# STM32F746ZGY7 register map
File version: 1.0
Registers are 32-bit, access not given, reset 0x0 unless marked. A register's access mark holds for its fields unless they carry their own. Offsets are from the block's base; [hi:lo] are bit positions; {n}, {i} and the like mark numbered series; 'fields as' and 'values as' point back to an identical list.

## ETH
Base 0x40028000
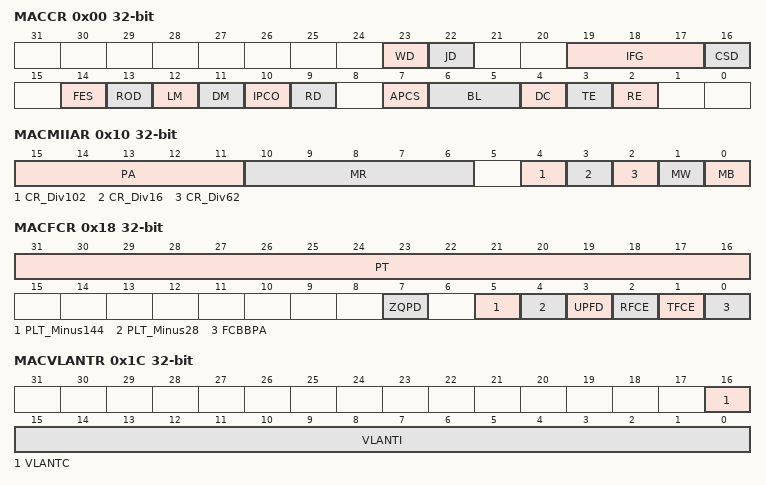
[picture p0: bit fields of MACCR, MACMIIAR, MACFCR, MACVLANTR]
0x00 MACCR
  [23] WD, [22] JD, [19:17] IFG, [16] CSD, [14] FES, [13] ROD, [12] LM, [11] DM, [10] IPCO, [9] RD, [7] APCS, [6:5] BL, [4] DC, [3] TE, [2] RE
0x04 MACFFR
  [31] RA, [10] HPF, [9] SAF, [8] SAIF, [7] PCF_ForwardAll, [7:6] PCF_ForwardPassedAddrFilter, [5] BFD, [4] PAM, [3] DAIF, [2] HM, [1] HU, [0] PM
0x08 MACHTHR
  [31:0] HTH
0x0C MACHTLR
  [31:0] HTL
0x10 MACMIIAR
  [15:11] PA, [10:6] MR, [4] CR_Div102, [3] CR_Div16, [2] CR_Div62, [1] MW, [0] MB
0x14 MACMIIDR
  [15:0] MD
0x18 MACFCR
  [31:16] PT, [7] ZQPD, [5] PLT_Minus144, [4] PLT_Minus28, [3] UPFD, [2] RFCE, [1] TFCE, [0] FCBBPA
0x1C MACVLANTR
  [16] VLANTC, [15:0] VLANTI
0x28 MACRWUFFR
  [31:0] D
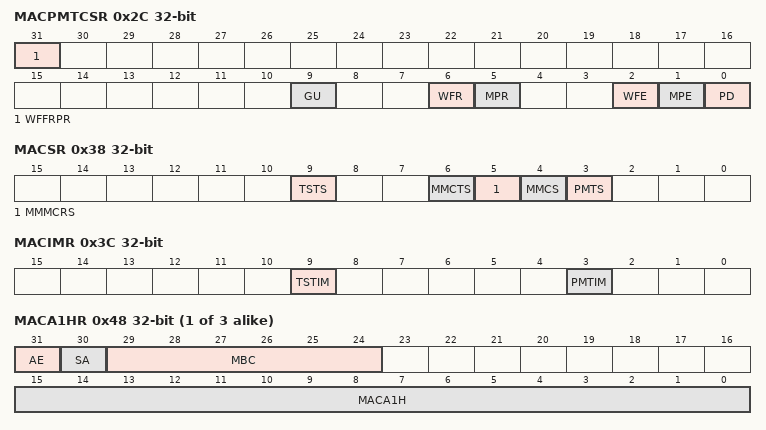
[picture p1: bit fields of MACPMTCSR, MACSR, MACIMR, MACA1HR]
0x2C MACPMTCSR
  [31] WFFRPR, [9] GU, [6] WFR, [5] MPR, [2] WFE, [1] MPE, [0] PD
0x34 MACDBGR
  [25] TFF, [24] TFNE, [22] TPWA, [21] TFRS_WAITING, [21:20] TFRS_WRITING, [19] MTP, [18] MTFCS_GENERATINGPCF, [17] MTFCS_WAITING, [16] MMTEA, [9] RFFL_ABOVEFCT, [9:8] RFFL_FULL, [6] RFRCS_STATUSREADING, [6:5] RFRCS_FLUSHING, [4] RFWRA, [2:1] MSFRWCS, [0] MMRPEA
0x38 MACSR
  [9] TSTS, [6] MMCTS, [5] MMMCRS, [4] MMCS, [3] PMTS
0x3C MACIMR
  [9] TSTIM, [3] PMTIM
0x40 MACA0HR
  [15:0] MACA0H
{0x44+8i} MACA{i}LR (i=0..3)
  [31:0] MACA{i}L
{0x40+8i} MACA{i}HR (i=1..3)
  [31] AE, [30] SA, [29:24] MBC, [15:0] MACA{i}H
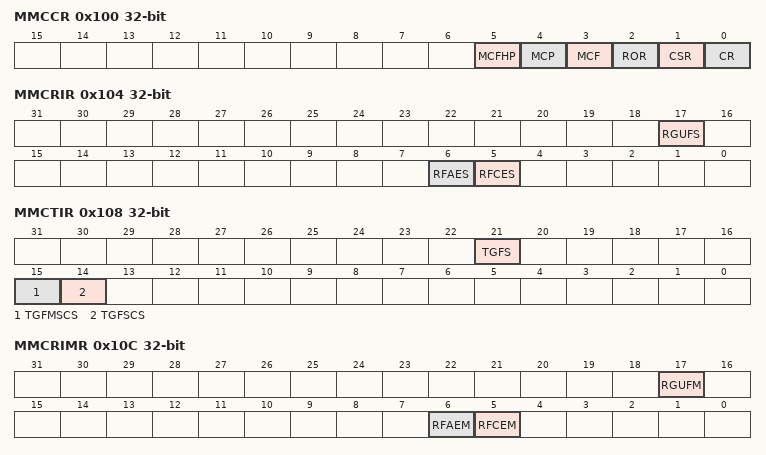
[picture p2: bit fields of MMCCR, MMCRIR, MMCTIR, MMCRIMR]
0x100 MMCCR
  [5] MCFHP, [4] MCP, [3] MCF, [2] ROR, [1] CSR, [0] CR
0x104 MMCRIR
  [17] RGUFS, [6] RFAES, [5] RFCES
0x108 MMCTIR
  [21] TGFS, [15] TGFMSCS, [14] TGFSCS
0x10C MMCRIMR
  [17] RGUFM, [6] RFAEM, [5] RFCEM
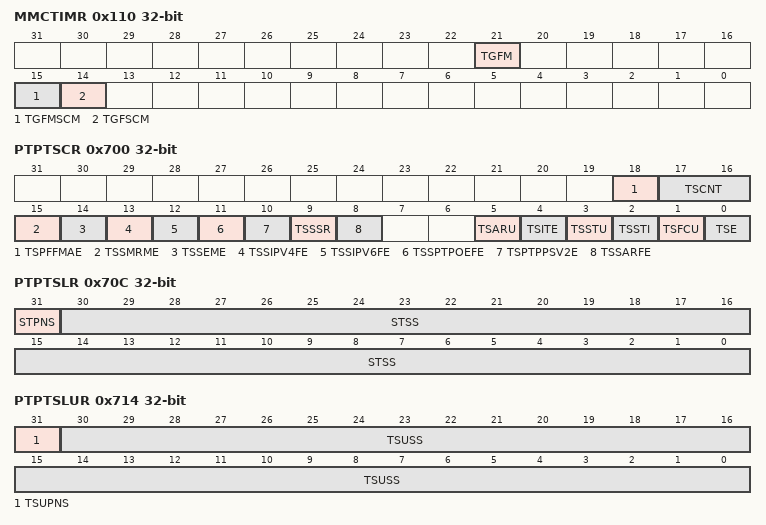
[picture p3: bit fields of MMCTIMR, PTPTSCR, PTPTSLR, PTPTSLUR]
0x110 MMCTIMR
  [21] TGFM, [15] TGFMSCM, [14] TGFSCM
0x14C MMCTGFSCCR
  [31:0] TGFSCC
0x150 MMCTGFMSCCR
  [31:0] TGFMSCC
0x168 MMCTGFCR
  [31:0] TGFC
0x194 MMCRFCECR
  [31:0] RFCEC
0x198 MMCRFAECR
  [31:0] RFAEC
0x1C4 MMCRGUFCR
  [31:0] RGUFC
0x700 PTPTSCR
  [18] TSPFFMAE, [17:16] TSCNT, [15] TSSMRME, [14] TSSEME, [13] TSSIPV4FE, [12] TSSIPV6FE, [11] TSSPTPOEFE, [10] TSPTPPSV2E, [9] TSSSR, [8] TSSARFE, [5] TSARU, [4] TSITE, [3] TSSTU, [2] TSSTI, [1] TSFCU, [0] TSE
0x704 PTPSSIR
  [7:0] STSSI
0x708 PTPTSHR
  [31:0] STS
0x70C PTPTSLR
  [31] STPNS, [30:0] STSS
0x710 PTPTSHUR
  [31:0] TSUS
0x714 PTPTSLUR
  [31] TSUPNS, [30:0] TSUSS
0x718 PTPTSAR
  [31:0] TSA
0x71C PTPTTHR
  [31:0] TTSH
0x720 PTPTTLR
  [31:0] TTSL
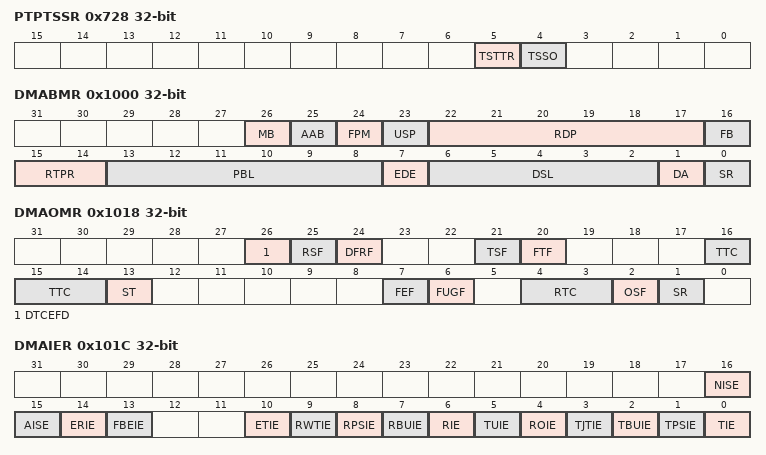
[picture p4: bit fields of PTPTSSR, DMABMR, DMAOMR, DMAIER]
0x728 PTPTSSR
  [5] TSTTR, [4] TSSO
0x72C PTPPPSCR
  [3:0] PPSFREQ
0x1000 DMABMR
  [26] MB, [25] AAB, [24] FPM, [23] USP, [22:17] RDP, [16] FB, [15:14] RTPR, [13:8] PBL, [7] EDE, [6:2] DSL, [1] DA, [0] SR
0x1004 DMATPDR
  [31:0] TPD
0x1008 DMARPDR
  [31:0] RPD
0x100C DMARDLAR
  [31:0] SRL
0x1010 DMATDLAR
  [31:0] STL
0x1014 DMASR
  [29] TSTS, [28] PMTS, [27] MMCS, [25] EBS_DescAccess, [24] EBS_ReadTransf, [23] EBS_DataTransfTx, [21] TPS_Waiting, [21:20] TPS_Reading, [19] RPS_Suspended, [18:17] RPS_Waiting, [16] NIS, [15] AIS, [14] ERS, [13] FBES, [10] ETS, [9] RWTS, [8] RPSS, [7] RBUS, [6] RS, [5] TUS, [4] ROS, [3] TJTS, [2] TBUS, [1] TPSS, [0] TS
0x1018 DMAOMR
  [26] DTCEFD, [25] RSF, [24] DFRF, [21] TSF, [20] FTF, [16:14] TTC, [13] ST, [7] FEF, [6] FUGF, [4:3] RTC, [2] OSF, [1] SR
0x101C DMAIER
  [16] NISE, [15] AISE, [14] ERIE, [13] FBEIE, [10] ETIE, [9] RWTIE, [8] RPSIE, [7] RBUIE, [6] RIE, [5] TUIE, [4] ROIE, [3] TJTIE, [2] TBUIE, [1] TPSIE, [0] TIE
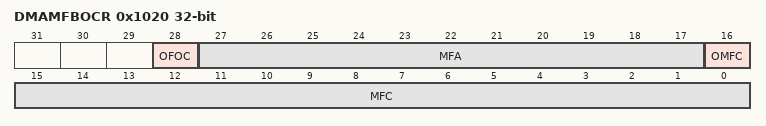
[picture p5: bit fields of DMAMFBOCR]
0x1020 DMAMFBOCR
  [28] OFOC, [27:17] MFA, [16] OMFC, [15:0] MFC
0x1024 DMARSWTR
0x1048 DMACHTDR
  [31:0] HTDAP
0x104C DMACHRDR
  [31:0] HRDAP
0x1050 DMACHTBAR
  [31:0] HTBAP
0x1054 DMACHRBAR
  [31:0] HRBAP

## USB_OTG_HS
Base 0x40040000
Same registers: USB_OTG_FS 0x50000000
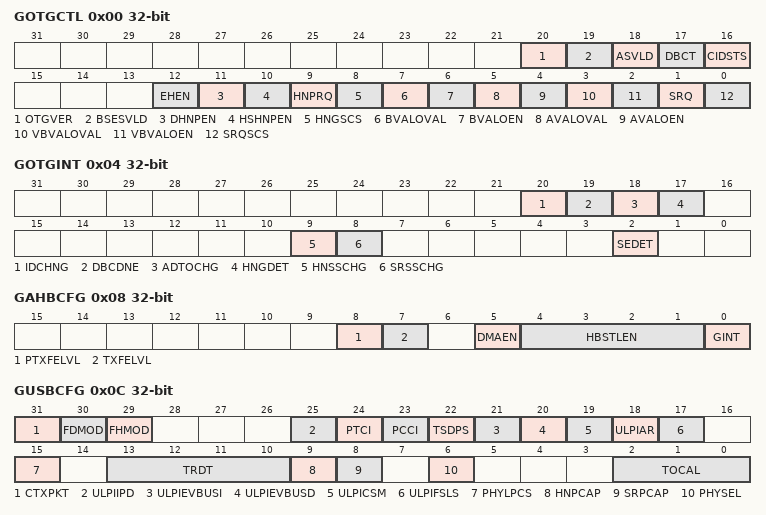
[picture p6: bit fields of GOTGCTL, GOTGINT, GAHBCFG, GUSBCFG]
0x00 GOTGCTL
  [20] OTGVER, [19] BSESVLD, [18] ASVLD, [17] DBCT, [16] CIDSTS, [12] EHEN, [11] DHNPEN, [10] HSHNPEN, [9] HNPRQ, [8] HNGSCS, [7] BVALOVAL, [6] BVALOEN, [5] AVALOVAL, [4] AVALOEN, [3] VBVALOVAL, [2] VBVALOEN, [1] SRQ, [0] SRQSCS
0x04 GOTGINT
  [20] IDCHNG, [19] DBCDNE, [18] ADTOCHG, [17] HNGDET, [9] HNSSCHG, [8] SRSSCHG, [2] SEDET
0x08 GAHBCFG
  [8] PTXFELVL, [7] TXFELVL, [5] DMAEN, [4:1] HBSTLEN, [0] GINT
0x0C GUSBCFG
  [31] CTXPKT, [30] FDMOD, [29] FHMOD, [25] ULPIIPD, [24] PTCI, [23] PCCI, [22] TSDPS, [21] ULPIEVBUSI, [20] ULPIEVBUSD, [19] ULPICSM, [18] ULPIAR, [17] ULPIFSLS, [15] PHYLPCS, [13:10] TRDT, [9] HNPCAP, [8] SRPCAP, [6] PHYSEL, [2:0] TOCAL
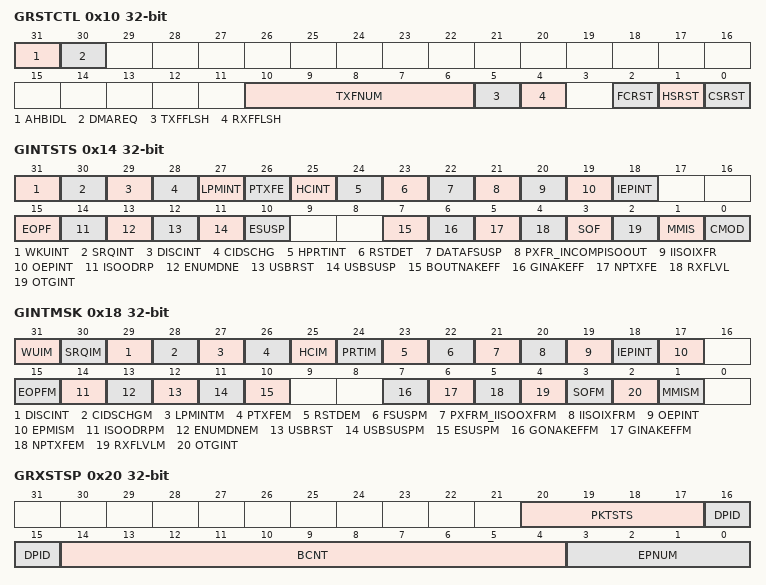
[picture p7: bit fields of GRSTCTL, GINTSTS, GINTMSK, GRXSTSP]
0x10 GRSTCTL
  [31] AHBIDL, [30] DMAREQ, [10:6] TXFNUM, [5] TXFFLSH, [4] RXFFLSH, [2] FCRST, [1] HSRST, [0] CSRST
0x14 GINTSTS
  [31] WKUINT, [30] SRQINT, [29] DISCINT, [28] CIDSCHG, [27] LPMINT, [26] PTXFE, [25] HCINT, [24] HPRTINT, [23] RSTDET, [22] DATAFSUSP, [21] PXFR_INCOMPISOOUT, [20] IISOIXFR, [19] OEPINT, [18] IEPINT, [15] EOPF, [14] ISOODRP, [13] ENUMDNE, [12] USBRST, [11] USBSUSP, [10] ESUSP, [7] BOUTNAKEFF, [6] GINAKEFF, [5] NPTXFE, [4] RXFLVL, [3] SOF, [2] OTGINT, [1] MMIS, [0] CMOD
0x18 GINTMSK
  [31] WUIM, [30] SRQIM, [29] DISCINT, [28] CIDSCHGM, [27] LPMINTM, [26] PTXFEM, [25] HCIM, [24] PRTIM, [23] RSTDEM, [22] FSUSPM, [21] PXFRM_IISOOXFRM, [20] IISOIXFRM, [19] OEPINT, [18] IEPINT, [17] EPMISM, [15] EOPFM, [14] ISOODRPM, [13] ENUMDNEM, [12] USBRST, [11] USBSUSPM, [10] ESUSPM, [7] GONAKEFFM, [6] GINAKEFFM, [5] NPTXFEM, [4] RXFLVLM, [3] SOFM, [2] OTGINT, [1] MMISM
0x1C GRXSTSR
0x20 GRXSTSP
  [20:17] PKTSTS, [16:15] DPID, [14:4] BCNT, [3:0] EPNUM
0x24 GRXFSIZ
  [15:0] RXFD
0x28 DIEPTXF0_HNPTXFSIZ
0x2C HNPTXSTS
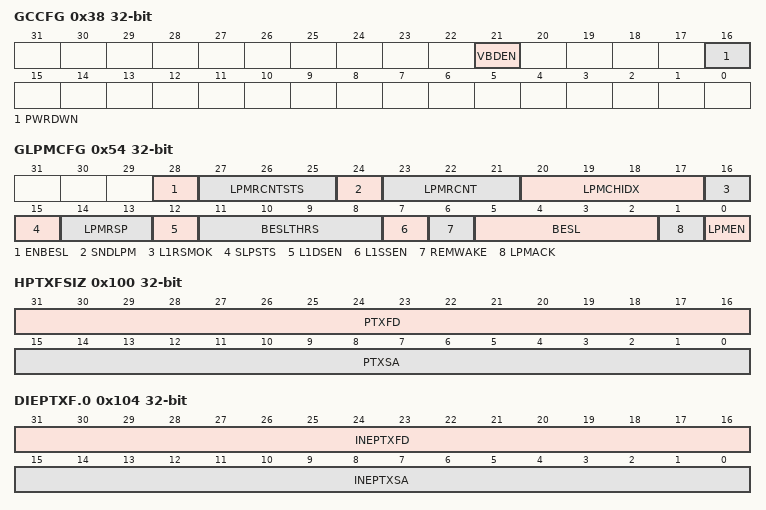
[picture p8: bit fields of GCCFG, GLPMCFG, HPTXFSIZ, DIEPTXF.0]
0x38 GCCFG
  [21] VBDEN, [16] PWRDWN
0x3C CID
  [31:0] PRODUCT_ID
0x4C GHWCFG3
0x54 GLPMCFG
  [28] ENBESL, [27:25] LPMRCNTSTS, [24] SNDLPM, [23:21] LPMRCNT, [20:17] LPMCHIDX, [16] L1RSMOK, [15] SLPSTS, [14:13] LPMRSP, [12] L1DSEN, [11:8] BESLTHRS, [7] L1SSEN, [6] REMWAKE, [5:2] BESL, [1] LPMACK, [0] LPMEN
0x5C GDFIFOCFG
0x100 HPTXFSIZ
  [31:16] PTXFD, [15:0] PTXSA
0x104 DIEPTXF.0
  [31:16] INEPTXFD, [15:0] INEPTXSA
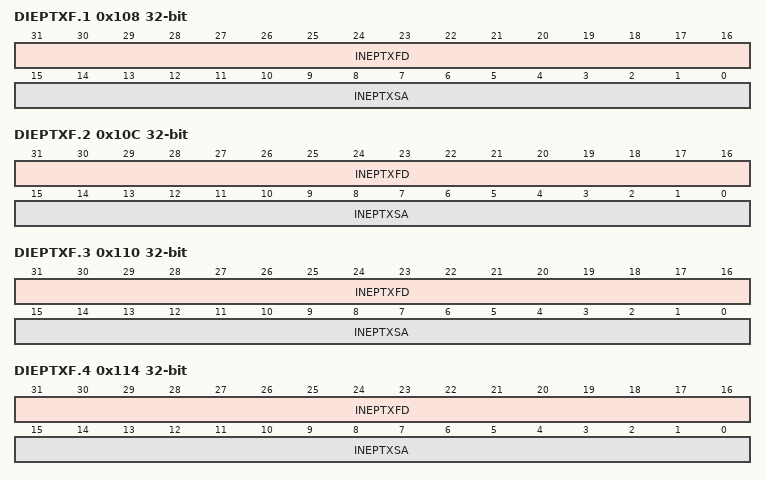
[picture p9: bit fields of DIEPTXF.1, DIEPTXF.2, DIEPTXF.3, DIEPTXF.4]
0x108 DIEPTXF.1
  [31:16] INEPTXFD, [15:0] INEPTXSA
0x10C DIEPTXF.2
  [31:16] INEPTXFD, [15:0] INEPTXSA
0x110 DIEPTXF.3
  [31:16] INEPTXFD, [15:0] INEPTXSA
0x114 DIEPTXF.4
  [31:16] INEPTXFD, [15:0] INEPTXSA
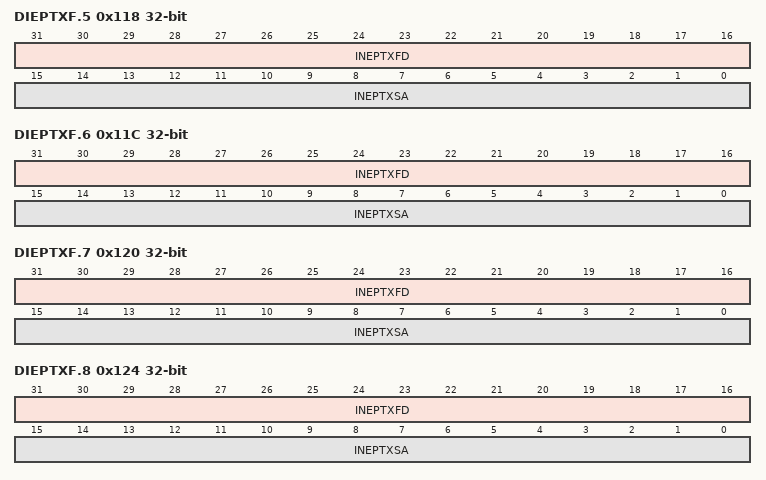
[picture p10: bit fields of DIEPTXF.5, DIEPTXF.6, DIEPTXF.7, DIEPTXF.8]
0x118 DIEPTXF.5
  [31:16] INEPTXFD, [15:0] INEPTXSA
0x11C DIEPTXF.6
  [31:16] INEPTXFD, [15:0] INEPTXSA
0x120 DIEPTXF.7
  [31:16] INEPTXFD, [15:0] INEPTXSA
0x124 DIEPTXF.8
  [31:16] INEPTXFD, [15:0] INEPTXSA
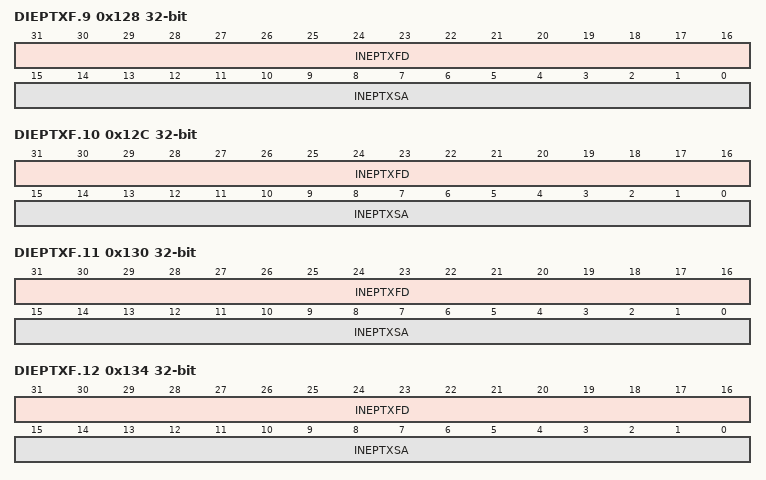
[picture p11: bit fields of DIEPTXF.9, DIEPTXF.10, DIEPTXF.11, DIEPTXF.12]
0x128 DIEPTXF.9
  [31:16] INEPTXFD, [15:0] INEPTXSA
0x12C DIEPTXF.10
  [31:16] INEPTXFD, [15:0] INEPTXSA
0x130 DIEPTXF.11
  [31:16] INEPTXFD, [15:0] INEPTXSA
0x134 DIEPTXF.12
  [31:16] INEPTXFD, [15:0] INEPTXSA
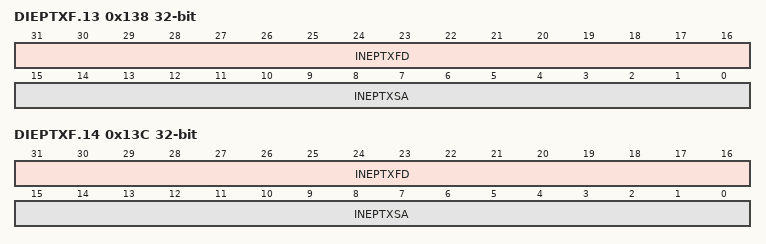
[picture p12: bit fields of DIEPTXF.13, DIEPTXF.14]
0x138 DIEPTXF.13
  [31:16] INEPTXFD, [15:0] INEPTXSA
0x13C DIEPTXF.14
  [31:16] INEPTXFD, [15:0] INEPTXSA

## DCMI
Base 0x50050000
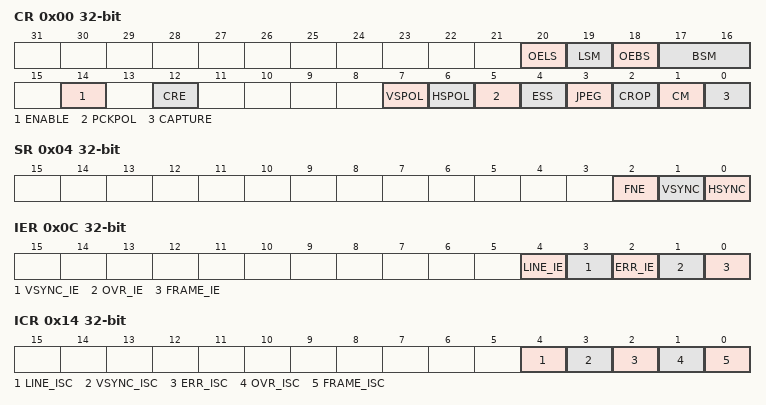
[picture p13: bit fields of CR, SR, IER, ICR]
0x00 CR
  [20] OELS, [19] LSM, [18] OEBS, [17:16] BSM, [14] ENABLE, [12] CRE, [7] VSPOL, [6] HSPOL, [5] PCKPOL, [4] ESS, [3] JPEG, [2] CROP, [1] CM, [0] CAPTURE
0x04 SR
  [2] FNE, [1] VSYNC, [0] HSYNC
0x08 RISR
0x0C IER
  [4] LINE_IE, [3] VSYNC_IE, [2] ERR_IE, [1] OVR_IE, [0] FRAME_IE
0x10 MISR
0x14 ICR
  [4] LINE_ISC, [3] VSYNC_ISC, [2] ERR_ISC, [1] OVR_ISC, [0] FRAME_ISC
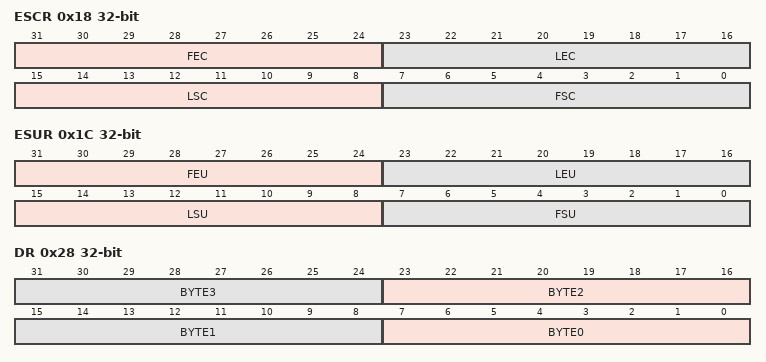
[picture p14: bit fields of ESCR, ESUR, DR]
0x18 ESCR
  [31:24] FEC, [23:16] LEC, [15:8] LSC, [7:0] FSC
0x1C ESUR
  [31:24] FEU, [23:16] LEU, [15:8] LSU, [7:0] FSU
0x20 CWSTRTR
0x24 CWSIZER
0x28 DR
  [8n+7:8n] BYTE{n} (n=0..3)

## RNG
Base 0x50060800
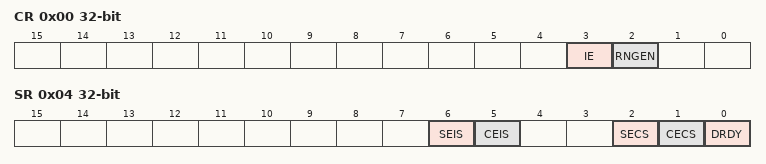
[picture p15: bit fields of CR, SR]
0x00 CR
  [3] IE, [2] RNGEN
0x04 SR
  [6] SEIS, [5] CEIS, [2] SECS, [1] CECS, [0] DRDY
0x08 DR

## FMC_Bank1
Base 0xA0000000
0x00 BTCR.0
0x04 BTCR.1
0x08 BTCR.2
0x0C BTCR.3
0x10 BTCR.4
0x14 BTCR.5
0x18 BTCR.6
0x1C BTCR.7

## FMC_Bank3
Base 0xA0000080
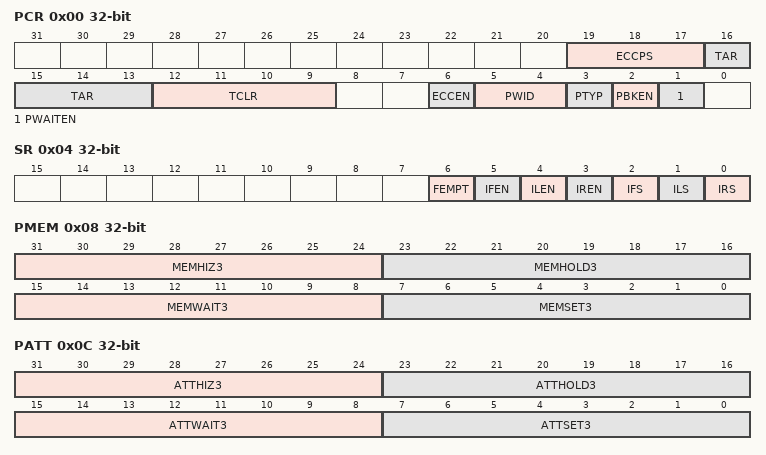
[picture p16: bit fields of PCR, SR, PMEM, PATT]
0x00 PCR
  [19:17] ECCPS, [16:13] TAR, [12:9] TCLR, [6] ECCEN, [5:4] PWID, [3] PTYP, [2] PBKEN, [1] PWAITEN
0x04 SR
  [6] FEMPT, [5] IFEN, [4] ILEN, [3] IREN, [2] IFS, [1] ILS, [0] IRS
0x08 PMEM
  [31:24] MEMHIZ3, [23:16] MEMHOLD3, [15:8] MEMWAIT3, [7:0] MEMSET3
0x0C PATT
  [31:24] ATTHIZ3, [23:16] ATTHOLD3, [15:8] ATTWAIT3, [7:0] ATTSET3
0x14 ECCR
  [31:0] ECC3

## FMC_Bank1E
Base 0xA0000104
0x00 BWTR.0
  [29:28] ACCMOD, [19:16] BUSTURN, [15:8] DATAST, [7:4] ADDHLD, [3:0] ADDSET
0x04 BWTR.1
  fields as BWTR.0
0x08 BWTR.2
  fields as BWTR.0
0x0C BWTR.3
  fields as BWTR.0
0x10 BWTR.4
0x14 BWTR.5
0x18 BWTR.6

## FMC_Bank5_6
Base 0xA0000140
0x00 SDCR.0
  [14:13] RPIPE, [12] RBURST, [11:10] SDCLK, [9] WP, [8:7] CAS, [6] NB, [5:4] MWID, [3:2] NR, [1:0] NC
0x04 SDCR.1
  fields as SDCR.0
0x08 SDTR.0
  [27:24] TRCD, [23:20] TRP, [19:16] TWR, [15:12] TRC, [11:8] TRAS, [7:4] TXSR, [3:0] TMRD
0x0C SDTR.1
  fields as SDTR.0
0x10 SDCMR
  [21:9] MRD, [8:5] NRFS, [4] CTB1, [3] CTB2, [2:0] MODE
0x14 SDRTR
  [14] REIE, [13:1] COUNT, [0] CRE
0x18 SDSR
  [5] BUSY, [4:3] MODES2, [2:1] MODES1, [0] RE

## QUADSPI
Base 0xA0001000
0x00 CR
  [31:24] PRESCALER, [23] PMM, [22] APMS, [20] TOIE, [19] SMIE, [18] FTIE, [17] TCIE, [16] TEIE, [12:8] FTHRES, [7] FSEL, [6] DFM, [4] SSHIFT, [3] TCEN, [2] DMAEN, [1] ABORT, [0] EN
0x04 DCR
  [20:16] FSIZE, [10:8] CSHT, [0] CKMODE
0x08 SR
  [13:8] FLEVEL, [5] BUSY, [4] TOF, [3] SMF, [2] FTF, [1] TCF, [0] TEF
0x0C FCR
  [4] CTOF, [3] CSMF, [1] CTCF, [0] CTEF
0x10 DLR
  [31:0] DL
0x14 CCR
  [31] DDRM, [30] DHHC, [28] SIOO, [27:26] FMODE, [25:24] DMODE, [22:18] DCYC, [17:16] ABSIZE, [15:14] ABMODE, [13:12] ADSIZE, [11:10] ADMODE, [9:8] IMODE, [7:0] INSTRUCTION
0x18 AR
  [31:0] ADDRESS
0x1C ABR
  [31:0] ALTERNATE
0x20 DR
  [31:0] DATA
0x24 PSMKR
  [31:0] MASK
0x28 PSMAR
  [31:0] MATCH
0x2C PIR
  [15:0] INTERVAL
0x30 LPTR
  [15:0] TIMEOUT

## DBGMCU
Base 0xE0042000
0x00 IDCODE
  [31:16] REV_ID, [11:0] DEV_ID
0x04 CR
  [7:6] TRACE_MODE, [5] TRACE_IOEN, [2] DBG_STANDBY, [1] DBG_STOP, [0] DBG_SLEEP
0x08 APB1FZ
  [26] DBG_CAN2_STOP, [25] DBG_CAN1_STOP, [23] DBG_I2C3_SMBUS_TIMEOUT, [22] DBG_I2C2_SMBUS_TIMEOUT, [21] DBG_I2C1_SMBUS_TIMEOUT, [12] DBG_IWDG_STOP, [11] DBG_WWDG_STOP, [10] DBG_RTC_STOP, [9] DBG_LPTIM1_STOP, [8] DBG_TIM14_STOP, [7] DBG_TIM13_STOP, [6] DBG_TIM12_STOP, [n-2] DBG_TIM{n}_STOP (n=2..7)
0x0C APB2FZ
  [18] DBG_TIM11_STOP, [17] DBG_TIM10_STOP, [16] DBG_TIM9_STOP, [1] DBG_TIM8_STOP, [0] DBG_TIM1_STOP
